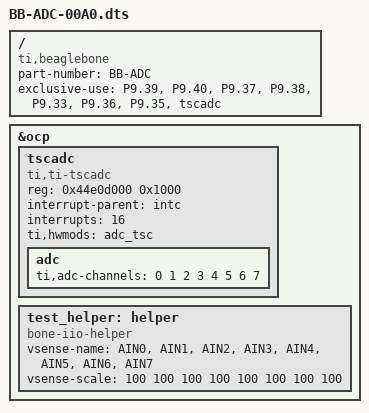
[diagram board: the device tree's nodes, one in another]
/*
 * Copyright (C) 2012 Texas Instruments Incorporated - http://www.ti.com/
 *
 * This program is free software; you can redistribute it and/or modify
 * it under the terms of the GNU General Public License version 2 as
 * published by the Free Software Foundation.
 */
/dts-v1/;
/plugin/;

/ {
	compatible = "ti,beaglebone", "ti,beaglebone-black", "ti,beaglebone-green";

	/* identification */
	part-number = "BB-ADC";

	/* state the resources this cape uses */
	exclusive-use =
		/* the pin header uses */
		"P9.39",	/* AIN0 */
		"P9.40",	/* AIN1 */
		"P9.37",	/* AIN2 */
		"P9.38",	/* AIN3 */
		"P9.33",	/* AIN4 */
		"P9.36",	/* AIN5 */
		"P9.35",	/* AIN6 */
		/* the hardware IP uses */
		"tscadc";

	fragment@0 {
		target = <&ocp>;
		__overlay__ {
			/* avoid stupid warning */
			#address-cells = <1>;
			#size-cells = <1>;

			tscadc {
				compatible = "ti,ti-tscadc";
				reg = <0x44e0d000 0x1000>;

				interrupt-parent = <&intc>;
				interrupts = <16>;
				ti,hwmods = "adc_tsc";
				status = "okay";

				adc {
					ti,adc-channels = <0 1 2 3 4 5 6 7>;
				};
			};

			test_helper: helper {
				compatible = "bone-iio-helper";
				vsense-name  = "AIN0", "AIN1", "AIN2", "AIN3", "AIN4", "AIN5", "AIN6", "AIN7";
				vsense-scale = <100     100     100     100     100     100     100     100>;
				status = "okay";
			};
		};
	};
};
